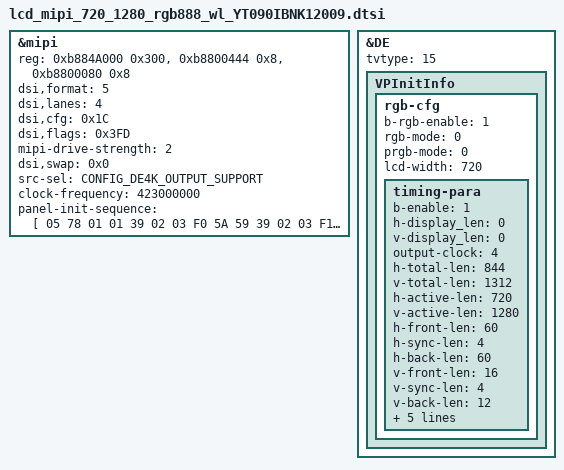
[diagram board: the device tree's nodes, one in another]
&mipi {
	reg = <0xb884A000 0x300>, <0xb8800444 0x8>,<0xb8800080 0x8>;

	/*
	 * MIPI_COLOR_RGB565_0	=	0
	 * MIPI_COLOR_RGB565_1	=	1
	 * MIPI_COLOR_RGB565_2	=	2
	 * MIPI_COLOR_RGB666_0	=	3
	 * MIPI_COLOR_RGB666_1	=	4
	 * MIPI_COLOR_RGB888	=	5
	 */
	dsi,format =<5>;

	dsi,lanes = <4>;

	/*
	 * bit 6:5 :Generic interface read-back Virtual Channel identification.
	 * bit 4 :Enables CRC reception and error reporting.
	 * bit 3 :Enables ECC reception, error correction and reporting
	 * bit 2 :MIPI_Bus_Turn_request.
	 * bit 1 :Enables EOTp reception.
	 * bit 0 :Enables EOTp transmission.
	 */
	dsi,cfg = <0x1C>;

	/* If there is no "dsi,flags", "dsi,flags" = <0x3FD>;
	 * bit 11: Enables the request for an acknowledge response at the end of a fram
	 * bit 10: Enables the transmission of null packets in the HACT period
	 * bit 9:  Enables the transmission of multi video packets in the HACT period
	 * bit 8:  Enables return to Low Power inside HFP period when timing allows.
	 * bit 7:  Enables return to Low Power inside HBP period when timing allows
	 * bit 6:  Enables return to Low Power inside VACT period when timing allows.
	 * bit 5:  Enables return to Low Power inside VFP period when timing allows
	 * bit 4:  Enables return to Low Power inside VBP period when timing allows
	 * bit 3:  Enables return to Low Power inside VSA period when timing allows
	 * bit 2:1 Selects video mode transmission type. 0: Non-burst with Sync pulses; 1: Non-burst with Sync events; 2-3: Burst with Sync pulses.
	 * bit 0:  Enables DPI Video mode transmission.
	 */
	dsi,flags = <0x3FD>;

	/*
	 * 0: MIPI_DRIVE_STRENGTH_MIDIMUN,
	 * 1: MIPI_DRIVE_STRENGTH_MIDDLE,
	 * 2: MIPI_DRIVE_STRENGTH_BIGGER, default
	 * 3: MIPI_DRIVE_STRENGTH_MAXIMUM,
	*/
	mipi-drive-strength = <2>;

	/*
	 * bit 4 : MIPI_DSI_DATA3_LANE_NP_SWAP
	 * bit 3 : MIPI_DSI_DATA2_LANE_NP_SWAP
	 * bit 2 : MIPI_DSI_DATA1_LANE_NP_SWAP
	 * bit 1 : MIPI_DSI_DATA0_LANE_NP_SWAP
	 * bit 0 : MIPI_DSI_CLOCK_LANE_NP_SWAP
	 */

	dsi,swap = <0x0>;
	/*
	 * 0: E_SRC_SEL_FXDE = 0
	 * 1: E_SRC_SEL_4KDE
	 * 2: E_SRC_SEL_HDMI_RX
	 */
	src-sel = <CONFIG_DE4K_OUTPUT_SUPPORT>;
	clock-frequency = <423000000>;
	//status = "okay";
};

&DE {
	tvtype = <15>;
	VPInitInfo {
		rgb-cfg{
			b-rgb-enable = <1>;
			/*
			 * 0: MODE_PRGB
			 * 1: MODE_SRGB
			 */
			rgb-mode = <0>;
			/*
			 * 0: MODE_PRGB_888_10bit
			 * 1: MODE_PRGB_666
			 */
			prgb-mode = <0>;
			lcd-width = <720>;
			timing-para {
				/* bool type, 0 or 1*/
				b-enable = <1>;

				h-display_len = <0>;
				v-display_len = <0>;

				/*
				 * VPO_RGB_CLOCK_27M = 1,
				 * VPO_RGB_CLOCK_33M = 2,
				 * VPO_RGB_CLOCK_49M = 3,
				 * VPO_RGB_CLOCK_66M = 4,
				 * VPO_RGB_CLOCK_74M = 5,
				 * VPO_RGB_CLOCK_85M = 6,
				 * VPO_RGB_CLOCK_108M = 7,
				 * VPO_RGB_CLOCK_6_6M = 8,
				 * VPO_RGB_CLOCK_9M = 9,
				 * VPO_RGB_CLOCK_39_6M = 10,
				 * VPO_RGB_CLOCK_74_25M = 11,
				 * VPO_RGB_CLOCK_148_5M = 12,
				 * VPO_RGB_CLOCK_54M = 13,
				 * VPO_RGB_CLOCK_132M = 14,//H1600
				 * VPO_RGB_CLOCK_297M = 15,//H1600 only De4k
				 * VPO_RGB_CLOCK_DPLL = 0xFF,//H1600
				*/
				output-clock = <4>;

				h-total-len = <844>;
				v-total-len = <1312>;

				h-active-len = <720>;
				v-active-len = <1280>;

				h-front-len = <60>;
				h-sync-len = <4>;
				h-back-len = <60>;

				v-front-len = <16>;
				v-sync-len = <4>;
				v-back-len = <12>;

				/* bool type, 0 or 1*/
				h-sync-level = <0>;
				/* bool type, 0 or 1*/
				v-sync-level = <0>;

				/* bool type, 0 or 1*/
				active-polarity = <1>;
				frame-rate = <60000>;

				/*
				31	De_dig_pll_en
				25:16	DE_DIG_PLL_M_ctrl
				13:8	DE_DIG_PLL_N_ctrl
				5:0	DE_DIG_PLL_L_ctrl
				de_digpll_clock = 24 *(M+1)/((N+1)*(L+1))
				*/
				dpll-clock-reg-value = <0x0>;
			};
		};
	};
};

&mipi{
	panel-init-sequence = [
		05 78 01 01
		39 02 03 F0 5A 59
		39 02 03 F1 A5 A6
		39 02 17 B4 0E 24 01 1C 08 1D 0C 12 10 04 06 03 03 03 03 03 03 03 03 03 03 03
		39 02 17 B3 0F 24 01 1C 08 1D 0D 13 11 05 07 03 03 03 03 03 03 03 03 03 03 03
		39 02 10 B0 76 54 76 57 33 33 14 31 24 00 00 9C 00 00 09
		39 02 0C B1 53 A0 00 85 0A 00 00 80 00 00 5F
		39 01 0B B2 37 09 08 8B 08 00 22 00 44 D9
		39 02 03 B6 83 83
		39 01 13 B7 01 01 09 0D 11 19 1D 15 00 25 21 00 00 00 00 02 F7 38
		39 01 05 B8 B8 52 02 CC
		39 01 03 BA 27 D3
		39 01 08 BD 43 0E 0E 70 70 32 10
		39 01 09 C1 00 0F 0E 01 00 36 3A 08
		39 01 03 C3 02 31
		39 01 09 C6 00 00 FF 00 00 FF 00 00
		39 03 06 C7 45 2B 41 00 02
		39 01 27 C8 7C 63 53 46 42 33 38 22 3C 3C 3D 5C 4B 53 45 41 33 20 06 7C 64 53 46 43 33 38 22 3C 3C 3D 5C 4B 53 45 41 33 20 06
		39 01 07 D4 00 00 00 32 04 51
		39 01 03 EF 00 00
		39 01 03 F1 5A 59
		39 01 03 F0 A5 A6
		05 78 01 11
		05 32 01 29
	];
};
